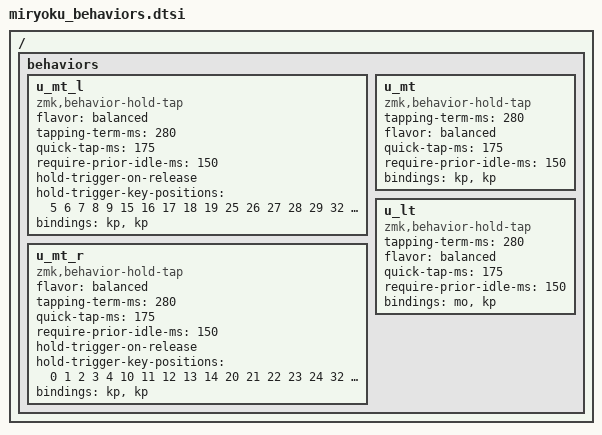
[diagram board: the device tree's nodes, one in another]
// Copyright 2022 Manna Harbour
// https://github.com/manna-harbour/miryoku

/ {
  behaviors {
    // Urob-style timeless home row mods for left hand
    // Triggers on right-side keys + thumbs (opposite hand)
    u_mt_l: u_mt_l {
      compatible = "zmk,behavior-hold-tap";
      #binding-cells = <2>;
      flavor = "balanced";
      tapping-term-ms = <280>;
      quick-tap-ms = <175>;
      require-prior-idle-ms = <150>;
      hold-trigger-on-release;
      hold-trigger-key-positions = <5 6 7 8 9 15 16 17 18 19 25 26 27 28 29 32 33 34>; // Right hand + thumbs
      bindings = <&kp>, <&kp>;
    };

    // Urob-style timeless home row mods for right hand
    // Triggers on left-side keys + thumbs (opposite hand)
    u_mt_r: u_mt_r {
      compatible = "zmk,behavior-hold-tap";
      #binding-cells = <2>;
      flavor = "balanced";
      tapping-term-ms = <280>;
      quick-tap-ms = <175>;
      require-prior-idle-ms = <150>;
      hold-trigger-on-release;
      hold-trigger-key-positions = <0 1 2 3 4 10 11 12 13 14 20 21 22 23 24 32 33 34>; // Left hand + thumbs
      bindings = <&kp>, <&kp>;
    };

    // Keep u_mt for non-home-row mod-taps (backward compatibility)
    u_mt: u_mt {
      compatible = "zmk,behavior-hold-tap";
      #binding-cells = <2>;
      tapping-term-ms = <280>;
      flavor = "balanced";
      quick-tap-ms = <175>;
      require-prior-idle-ms = <150>;
      bindings = <&kp>, <&kp>;
    };

    // Layer-tap behavior with improved timing
    u_lt: u_lt {
      compatible = "zmk,behavior-hold-tap";
      #binding-cells = <2>;
      tapping-term-ms = <280>;
      flavor = "balanced";
      quick-tap-ms = <175>;
      require-prior-idle-ms = <150>;
      bindings = <&mo>, <&kp>;
    };
  };
};
